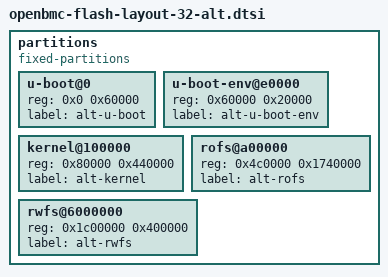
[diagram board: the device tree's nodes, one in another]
// SPDX-License-Identifier: GPL-2.0+
/*
 * Copyright (C) 2020 Bytedance.
 */

partitions {
	compatible = "fixed-partitions";
	#address-cells = <1>;
	#size-cells = <1>;

	u-boot@0 {
		reg = <0x0 0x60000>;
		label = "alt-u-boot";
	};

	u-boot-env@e0000 {
		reg = <0x60000 0x20000>;
		label = "alt-u-boot-env";
	};

	kernel@100000 {
		reg = <0x80000 0x440000>;
		label = "alt-kernel";
	};

	rofs@a00000 {
		reg = <0x4c0000 0x1740000>;
		label = "alt-rofs";
	};

	rwfs@6000000 {
		reg = <0x1c00000 0x400000>;
		label = "alt-rwfs";
	};
};
